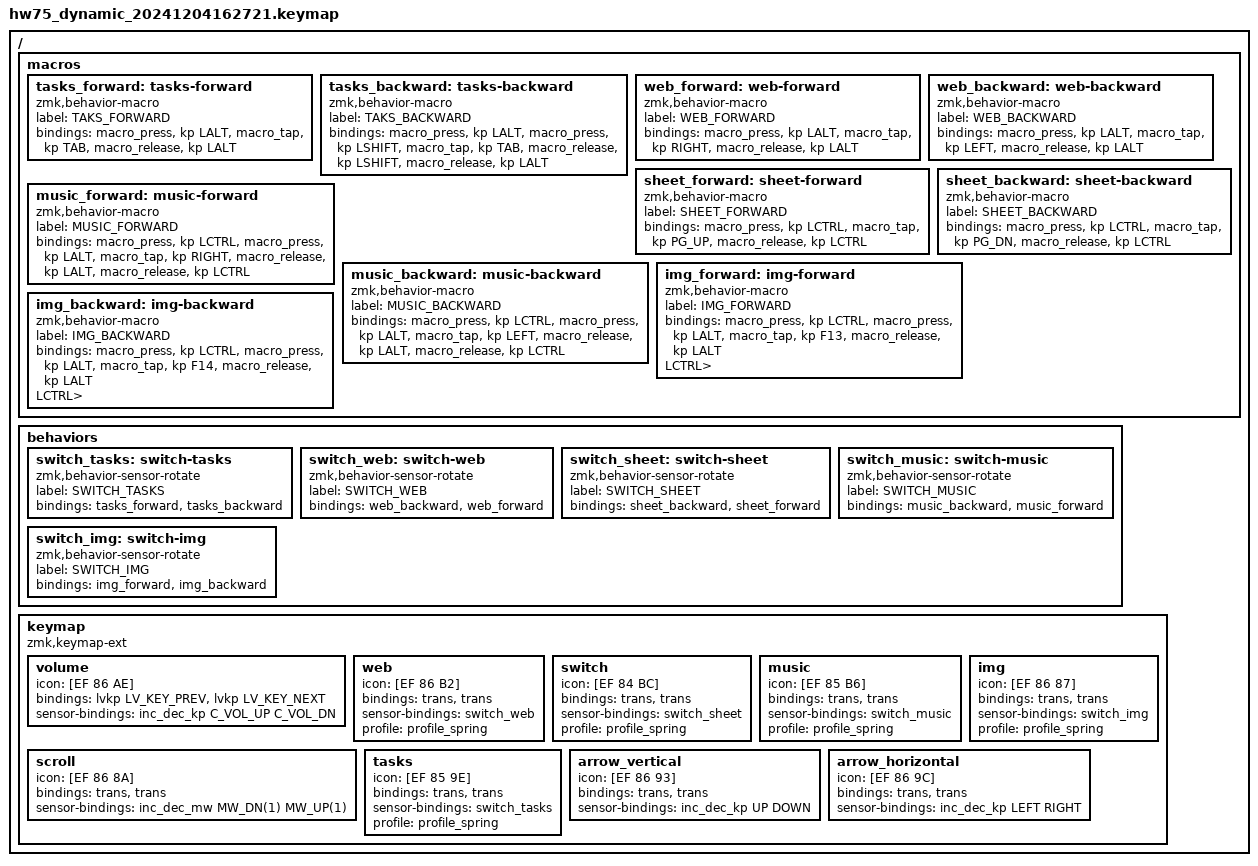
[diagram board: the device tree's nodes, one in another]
/*
 * Copyright (c) 2022 The ZMK Contributors
 * SPDX-License-Identifier: MIT
 * chr(int(' ',16)).encode('utf-8')
 */

#include <behaviors.dtsi>
#include <behaviors/lvgl_key_press.dtsi>
#include <behaviors/sensor_rotate_mouse_wheel.dtsi>
#include <dt-bindings/zmk/keys.h>
#include <dt-bindings/zmk/rgb.h>
#include <dt-bindings/zmk/lvgl.h>
#include <dt-bindings/zmk/mouse.h>

/ {
	macros {
		tasks_forward: tasks-forward {
			label = "TAKS_FORWARD";
			compatible = "zmk,behavior-macro";
			#binding-cells = <0>;
			bindings = <&macro_press   &kp LALT>,
				   <&macro_tap     &kp TAB>,
				   <&macro_release &kp LALT>;
		};

		tasks_backward: tasks-backward {
			label = "TAKS_BACKWARD";
			compatible = "zmk,behavior-macro";
			#binding-cells = <0>;
			bindings = <&macro_press   &kp LALT>,
				   <&macro_press   &kp LSHIFT>,
				   <&macro_tap     &kp TAB>,
				   <&macro_release &kp LSHIFT>,
				   <&macro_release &kp LALT>;
		};

		web_forward: web-forward {
			label = "WEB_FORWARD";
			compatible = "zmk,behavior-macro";
			#binding-cells = <0>;
			bindings = <&macro_press   &kp LALT>,
				   <&macro_tap     &kp RIGHT>,
				   <&macro_release &kp LALT>;
		};

		web_backward: web-backward {
			label = "WEB_BACKWARD";
			compatible = "zmk,behavior-macro";
			#binding-cells = <0>;
			bindings = <&macro_press   &kp LALT>,
				   <&macro_tap     &kp LEFT>,
				   <&macro_release &kp LALT>;
		};

		sheet_forward: sheet-forward {
			label = "SHEET_FORWARD";
			compatible = "zmk,behavior-macro";
			#binding-cells = <0>;
			bindings = <&macro_press   &kp LCTRL>,
				   <&macro_tap     &kp PG_UP>,
				   <&macro_release &kp LCTRL>;
		};

		sheet_backward: sheet-backward {
			label = "SHEET_BACKWARD";
			compatible = "zmk,behavior-macro";
			#binding-cells = <0>;
			bindings = <&macro_press   &kp LCTRL>,
				   <&macro_tap     &kp PG_DN>,
				   <&macro_release &kp LCTRL>;
		};

		music_forward: music-forward {
			label = "MUSIC_FORWARD";
			compatible = "zmk,behavior-macro";
			#binding-cells = <0>;
			bindings = <&macro_press   &kp LCTRL>,
				   <&macro_press     &kp LALT>,
				   <&macro_tap     &kp RIGHT>,
				   <&macro_release &kp LALT>,
				   <&macro_release &kp LCTRL>;
		};

		music_backward: music-backward {
			label = "MUSIC_BACKWARD";
			compatible = "zmk,behavior-macro";
			#binding-cells = <0>;
			bindings = <&macro_press   &kp LCTRL>,
				   <&macro_press     &kp LALT>,
				   <&macro_tap     &kp LEFT>,
				   <&macro_release &kp LALT>,
				   <&macro_release &kp LCTRL>;
		};

        img_forward: img-forward {
			label = "IMG_FORWARD";
			compatible = "zmk,behavior-macro";
			#binding-cells = <0>;
			bindings = <&macro_press   &kp LCTRL>,
                    <&macro_press   &kp LALT>,
				   <&macro_tap     &kp F13>,
				   <&macro_release &kp LALT>;
                   <&macro_release &kp LCTRL>;
		};

		img_backward: img-backward {
			label = "IMG_BACKWARD";
			compatible = "zmk,behavior-macro";
			#binding-cells = <0>;
			bindings = <&macro_press   &kp LCTRL>,
                    <&macro_press   &kp LALT>,
				   <&macro_tap     &kp F14>,
				   <&macro_release &kp LALT>;
                   <&macro_release &kp LCTRL>;
		};
	};

	behaviors {
		switch_tasks: switch-tasks {
			compatible = "zmk,behavior-sensor-rotate";
			label = "SWITCH_TASKS";
			#sensor-binding-cells = <0>;
			bindings = <&tasks_forward>, <&tasks_backward>;
		};
		switch_web: switch-web {
			compatible = "zmk,behavior-sensor-rotate";
			label = "SWITCH_WEB";
			#sensor-binding-cells = <0>;
			bindings = <&web_backward>, <&web_forward>;
		};
		switch_sheet: switch-sheet {
			compatible = "zmk,behavior-sensor-rotate";
			label = "SWITCH_SHEET";
			#sensor-binding-cells = <0>;
			bindings = <&sheet_backward>, <&sheet_forward>;
		};
		switch_music: switch-music {
			compatible = "zmk,behavior-sensor-rotate";
			label = "SWITCH_MUSIC";
			#sensor-binding-cells = <0>;
			bindings = <&music_backward>, <&music_forward>;
		};
		switch_img: switch-img {
			compatible = "zmk,behavior-sensor-rotate";
			label = "SWITCH_IMG";
			#sensor-binding-cells = <0>;
			bindings = <&img_forward>, <&img_backward>;
		};
	};

	keymap {
		compatible = "zmk,keymap-ext", "zmk,keymap";

		volume {
			label = "音量";
			icon = [EF 86 AE];
			bindings = <&lvkp LV_KEY_PREV &lvkp LV_KEY_NEXT>;
			sensor-bindings = <&inc_dec_kp C_VOL_UP C_VOL_DN>;
		};

		web {
			label = "前退";
			icon = [EF 86 B2];
			bindings = <&trans &trans>;
			sensor-bindings = <&switch_web>;
			profile = <&profile_spring>;
		};

		switch {
			label = "切换";
			icon = [EF 84 BC];
			bindings = <&trans &trans>;
			sensor-bindings = <&switch_sheet>;
			profile = <&profile_spring>;
		};

		music {
			label = "音乐";
			icon = [EF 85 B6];
			bindings = <&trans &trans>;
			sensor-bindings = <&switch_music>;
			profile = <&profile_spring>;
		};

		img {
			label = "图片";
			icon = [EF 86 87];
			bindings = <&trans &trans>;
			sensor-bindings = <&switch_img>;
			profile = <&profile_spring>;
		};

		scroll {
			label = "滚动";
			icon = [EF 86 8A];
			bindings = <&trans &trans>;
			sensor-bindings = <&inc_dec_mw MW_DN(1) MW_UP(1)>;
		};

		tasks {
			label = "窗口";
			icon = [EF 85 9E];
			bindings = <&trans &trans>;
			sensor-bindings = <&switch_tasks>;
			profile = <&profile_spring>;
		};

		arrow_vertical {
			label = "上下";
			icon = [EF 86 93];
			bindings = <&trans &trans>;
			sensor-bindings = <&inc_dec_kp UP DOWN>;
		};

		arrow_horizontal {
			label = "左右";
			icon = [EF 86 9C];
			bindings = <&trans &trans>;
			sensor-bindings = <&inc_dec_kp LEFT RIGHT>;
		};
	};
};
